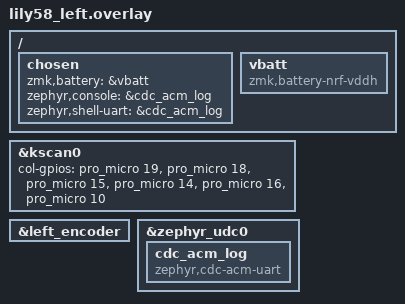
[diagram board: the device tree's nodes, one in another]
/*
 * Copyright (c) 2020 Pete Johanson
 *
 * SPDX-License-Identifier: MIT
 */

#include "lily58.dtsi"

&kscan0 {
    col-gpios
        = <&pro_micro 19 GPIO_ACTIVE_HIGH>
        , <&pro_micro 18 GPIO_ACTIVE_HIGH>
        , <&pro_micro 15 GPIO_ACTIVE_HIGH>
        , <&pro_micro 14 GPIO_ACTIVE_HIGH>
        , <&pro_micro 16 GPIO_ACTIVE_HIGH>
        , <&pro_micro 10 GPIO_ACTIVE_HIGH>
        ;
};

&left_encoder {
    status = "okay";
};
/ {
    chosen {
      zmk,battery = &vbatt;
    };

    vbatt: vbatt {
        compatible = "zmk,battery-nrf-vddh";
    };

    /* TEMP DEBUG: route console to a USB CDC-ACM for log capture. Revert after. */
    chosen {
        zephyr,console = &cdc_acm_log;
        zephyr,shell-uart = &cdc_acm_log;
    };
};

&zephyr_udc0 {
    cdc_acm_log: cdc_acm_log {
        compatible = "zephyr,cdc-acm-uart";
    };
};
